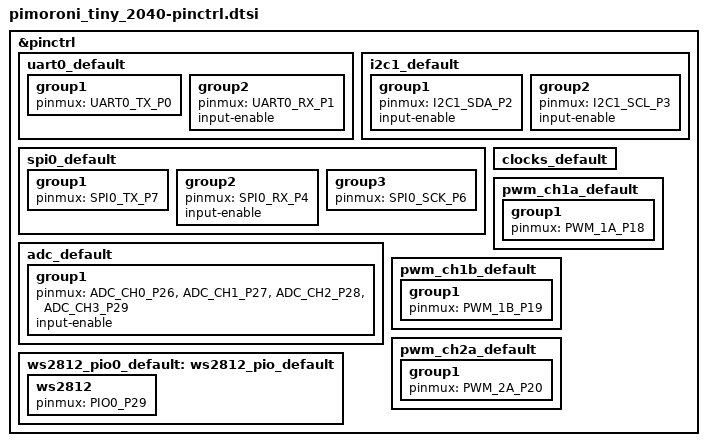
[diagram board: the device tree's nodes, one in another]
/*
 * Copyright (c) 2021, Yonatan Schachter
 * SPDX-License-Identifier: Apache-2.0
 */

#include <dt-bindings/pinctrl/rpi-pico-rp2040-pinctrl.h>

&pinctrl {
	uart0_default: uart0_default {
		group1 {
			pinmux = <UART0_TX_P0>;
		};
		group2 {
			pinmux = <UART0_RX_P1>;
			input-enable;
		};
	};

	i2c1_default: i2c1_default {
		group1 {
			pinmux = <I2C1_SDA_P2>;
			input-enable;
		};
		group2 {
			pinmux = <I2C1_SCL_P3>;
			input-enable;
		};
	};

	spi0_default: spi0_default {
		group1 {
			pinmux = <SPI0_TX_P7>;
		};
		group2 {
			pinmux = <SPI0_RX_P4>;
			input-enable;
		};
		group3 {
			pinmux = <SPI0_SCK_P6>;
		};
	};

	adc_default: adc_default {
		group1 {
			pinmux = <ADC_CH0_P26>, <ADC_CH1_P27>, <ADC_CH2_P28>, <ADC_CH3_P29>;
			input-enable;
		};
	};

	clocks_default: clocks_default {
	};

	/* This isn't actually on the pimoroni. TODO: Move this to my shield. */
	ws2812_pio0_default: ws2812_pio_default {
		ws2812 {
			pinmux = <PIO0_P29>;
		};
	};

	pwm_ch1a_default: pwm_ch1a_default {
		group1 {
			pinmux = <PWM_1A_P18>;
		};
	};

	pwm_ch1b_default: pwm_ch1b_default {
		group1 {
			pinmux = <PWM_1B_P19>;
		};
	};

	pwm_ch2a_default: pwm_ch2a_default {
		group1 {
			pinmux = <PWM_2A_P20>;
		};
	};
};
